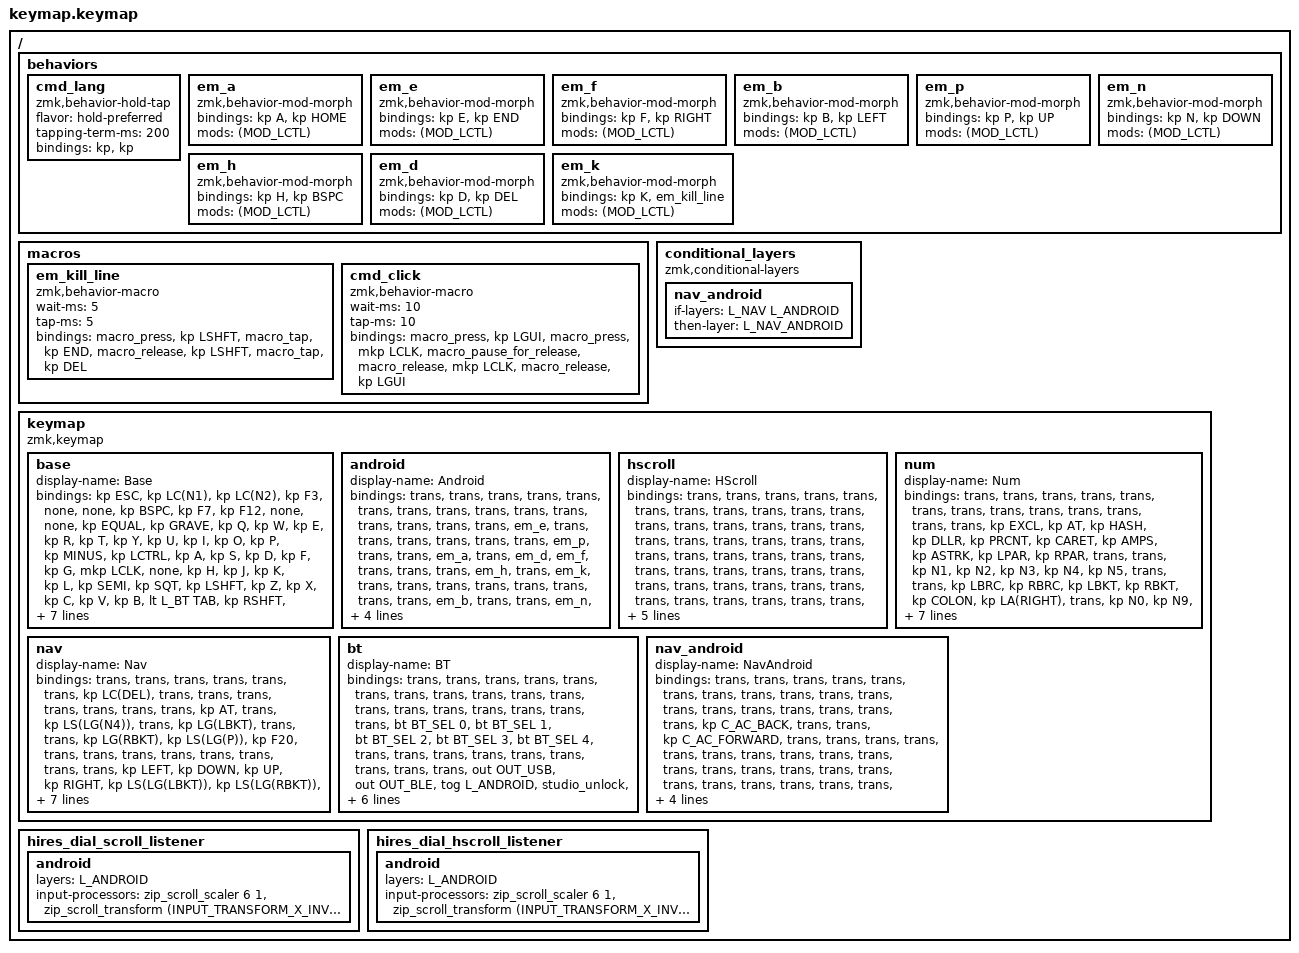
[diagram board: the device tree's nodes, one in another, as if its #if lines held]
/*
 * torabo-tsuki LP (L size) keymap
 *   - 右: トラックボール + 高分解能ダイヤル (central) / 左: モジュールなし (peripheral)
 *   - 右の BMP Boost 真下のキー (position 31) を高分解能ダイヤルモジュールに置換
 *     (BMP Boost Extender Mini 経由で接続。position 30 は通常のキー)
 *   - keymap_cheatsheet_keyball61-dual.pdf の配置をできるだけ再現 (マクロは未割当)
 *
 * Position map (L size, ダイヤル有効時):
 *
 *   0  1  2  3  4  5                    6  7  8  9 10 11
 *  12 13 14 15 16 17                   18 19 20 21 22 23
 *  24 25 26 27 28 29  30        [31]  32 33 34 35 36 37
 *  38 39 40 41 42 43  44          45   46 47 48 49 50 51
 *  52 53 54 55   56 57 58     59 60 (61 62) 63 64 65
 *                                    ^ボールで潰れる
 *  [31] = ダイヤルに置換 (スイッチなし)
 *  66 = ダイヤル押し込み (縦/横スクロールのトグル) / 回転は末尾の sensor-bindings で設定
 */

#include <behaviors.dtsi>
#include <dt-bindings/zmk/bt.h>
#include <dt-bindings/zmk/keys.h>
#include <dt-bindings/zmk/outputs.h>
#include <dt-bindings/zmk/pointing.h>
#include <dt-bindings/zmk/input_transform.h>

// レイヤー番号 (数字が大きいほど優先)
//   Android モードは Base の直上に置き、Num / Nav / BT の割り当てを上書きしないようにする
//   L_ANDROID を変えたら src/android_mode.c の ANDROID_MODE_LAYER も合わせる
#define L_BASE        0
#define L_ANDROID     1
#define L_HSCROLL     2
#define L_NUM         3
#define L_NAV         4
#define L_BT          5
#define L_NAV_ANDROID 6

#if defined(TORABO_TSUKI_LP_INPUT_HIRES_DIAL)
#include <behaviors/hires_dial.dtsi>
#endif

/ {
    behaviors {
        // タップで LANG (英数/かな)、長押し or 他キーと同時押しで修飾キー (⌘、Android モードの 57 は Ctrl)
        //   Mac は LANG1=かな / LANG2=英数 をそのまま解釈、Android (Gboard) でも IME 切替になる
        cmd_lang: cmd_lang {
            compatible = "zmk,behavior-hold-tap";
            #binding-cells = <2>;
            flavor = "hold-preferred";
            tapping-term-ms = <200>;
            bindings = <&kp>, <&kp>;
        };

        // Android 用 Emacs 風カーソル移動: 左 Ctrl (24) と同時押しのときだけ置き換える (Ctrl は外して送る)
        //   57 の長押しは Android モードでは右 Ctrl なので、57 + A / F などは普通の Ctrl ショートカットになる
        em_a: em_a {  // Ctrl+A → 行頭
            compatible = "zmk,behavior-mod-morph";
            #binding-cells = <0>;
            bindings = <&kp A>, <&kp HOME>;
            mods = <(MOD_LCTL)>;
        };
        em_e: em_e {  // Ctrl+E → 行末
            compatible = "zmk,behavior-mod-morph";
            #binding-cells = <0>;
            bindings = <&kp E>, <&kp END>;
            mods = <(MOD_LCTL)>;
        };
        em_f: em_f {  // Ctrl+F → →
            compatible = "zmk,behavior-mod-morph";
            #binding-cells = <0>;
            bindings = <&kp F>, <&kp RIGHT>;
            mods = <(MOD_LCTL)>;
        };
        em_b: em_b {  // Ctrl+B → ←
            compatible = "zmk,behavior-mod-morph";
            #binding-cells = <0>;
            bindings = <&kp B>, <&kp LEFT>;
            mods = <(MOD_LCTL)>;
        };
        em_p: em_p {  // Ctrl+P → ↑
            compatible = "zmk,behavior-mod-morph";
            #binding-cells = <0>;
            bindings = <&kp P>, <&kp UP>;
            mods = <(MOD_LCTL)>;
        };
        em_n: em_n {  // Ctrl+N → ↓
            compatible = "zmk,behavior-mod-morph";
            #binding-cells = <0>;
            bindings = <&kp N>, <&kp DOWN>;
            mods = <(MOD_LCTL)>;
        };
        em_h: em_h {  // Ctrl+H → Backspace
            compatible = "zmk,behavior-mod-morph";
            #binding-cells = <0>;
            bindings = <&kp H>, <&kp BSPC>;
            mods = <(MOD_LCTL)>;
        };
        em_d: em_d {  // Ctrl+D → Delete (カーソルの右を削除)
            compatible = "zmk,behavior-mod-morph";
            #binding-cells = <0>;
            bindings = <&kp D>, <&kp DEL>;
            mods = <(MOD_LCTL)>;
        };
        em_k: em_k {  // Ctrl+K → 行末まで削除 (下の em_kill_line マクロ)
            compatible = "zmk,behavior-mod-morph";
            #binding-cells = <0>;
            bindings = <&kp K>, <&em_kill_line>;
            mods = <(MOD_LCTL)>;
        };
    };

    macros {
        // Android 用 Ctrl+K: Shift+End で行末まで選択 → Delete
        //   行末で押した場合は選択が空なので Delete で次の行と結合される (Emacs と同じ)
        //   mod-morph の Ctrl マスクは K を離すと解除されるため、離す前に送り終わるよう間隔を短くしている
        em_kill_line: em_kill_line {
            compatible = "zmk,behavior-macro";
            #binding-cells = <0>;
            wait-ms = <5>;
            tap-ms = <5>;
            bindings
                = <&macro_press &kp LSHFT>
                , <&macro_tap &kp END>
                , <&macro_release &kp LSHFT>
                , <&macro_tap &kp DEL>
                ;
        };

        // ⌘ + 左クリック (押している間 ⌘ と左ボタンを押しっぱなし)
        cmd_click: cmd_click {
            compatible = "zmk,behavior-macro";
            #binding-cells = <0>;
            wait-ms = <10>;
            tap-ms = <10>;
            bindings
                = <&macro_press &kp LGUI>
                , <&macro_press &mkp LCLK>
                , <&macro_pause_for_release>
                , <&macro_release &mkp LCLK>
                , <&macro_release &kp LGUI>
                ;
        };
    };

    // Nav と Android モードが両方有効なときだけ NavAndroid レイヤーを有効にする
    conditional_layers {
        compatible = "zmk,conditional-layers";
        nav_android {
            if-layers = <L_NAV L_ANDROID>;
            then-layer = <L_NAV_ANDROID>;
        };
    };

    keymap {
        compatible = "zmk,keymap";

        // Layer 0: base
        base {
            display-name = "Base";
            bindings = <
&kp ESC    &kp LC(N1)         &kp LC(N2)  &kp F3   &none      &none                                                                    &kp BSPC  &kp F7  &kp F12    &none         &none                     &kp EQUAL
&kp GRAVE  &kp Q              &kp W       &kp E    &kp R      &kp T                                                                    &kp Y     &kp U   &kp I      &kp O         &kp P                     &kp MINUS
&kp LCTRL  &kp A              &kp S       &kp D    &kp F      &kp G      &mkp LCLK                            &none                    &kp H     &kp J   &kp K      &kp L         &kp SEMI                  &kp SQT
&kp LSHFT  &kp Z              &kp X       &kp C    &kp V      &kp B      &lt L_BT TAB                            &kp RSHFT                &kp N     &kp M   &kp COMMA  &kp DOT       &kp FSLH                  &kp BSLH
&none      &kp LALT           &none       &mo L_NAV &mo L_NUM     &cmd_lang LGUI LANG2   &kp SPACE    &lt L_NAV RET  &lt L_NUM LANG1   &none     &none          &cmd_lang RGUI LANG1  &mkp RCLK &mkp LCLK
#if defined(TORABO_TSUKI_LP_INPUT_HIRES_DIAL)
&tog L_HSCROLL
#endif
            >;
        };

        // Layer 1: Android モード (BT1 に切り替えると自動で ON、他の接続先で OFF: src/android_mode.c)
        //   BT レイヤーの 34 で手動トグルも可
        //   52 = ⌘、57 = タップで英数 / 長押しで右 Ctrl (Mac の ⌘ の代わり)
        //   A/E/F/B/P/N/H/D/K = 左 Ctrl (24) と同時押しで Emacs 風 (行頭/行末/矢印/Backspace/Delete/行末まで削除)。他は &trans
        //   ダイヤルの割り当ては持たない (下のレイヤーのものが使われる)
        //   ダイヤルのスクロールだけ、下の input-listener の上書きで速く・逆向きにする
        android {
            display-name = "Android";
            bindings = <
&trans  &trans  &trans  &trans  &trans  &trans                                                  &trans  &trans  &trans  &trans  &trans  &trans
&trans  &trans  &trans  &em_e  &trans  &trans  &trans  &trans  &trans  &trans  &em_p  &trans
&trans  &em_a  &trans  &em_d  &em_f  &trans  &trans  &trans  &em_h  &trans  &em_k  &trans  &trans  &trans
&trans  &trans  &trans  &trans  &trans  &em_b  &trans  &trans  &em_n  &trans  &trans  &trans  &trans  &trans
&kp LGUI  &trans  &trans  &trans  &trans  &cmd_lang RCTRL LANG2  &trans         &trans  &trans  &trans           &trans  &trans  &trans  &trans
#if defined(TORABO_TSUKI_LP_INPUT_HIRES_DIAL)
&trans
#endif
            >;
        };

        // Layer 2: ダイヤル横スクロール (ダイヤル押し込みでトグル)
        //   Base の直上に置くので、Num / Nav 中はそちらのダイヤル設定が優先される
        hscroll {
            display-name = "HScroll";
            bindings = <
&trans  &trans  &trans  &trans  &trans  &trans                                                  &trans  &trans  &trans  &trans  &trans  &trans
&trans  &trans  &trans  &trans  &trans  &trans                                                  &trans  &trans  &trans  &trans  &trans  &trans
&trans  &trans  &trans  &trans  &trans  &trans  &trans                         &trans           &trans  &trans  &trans  &trans  &trans  &trans
&trans  &trans  &trans  &trans  &trans  &trans  &trans                         &trans           &trans  &trans  &trans  &trans  &trans  &trans
&trans  &trans  &trans  &trans  &trans  &trans  &trans         &trans  &trans  &trans           &trans  &trans  &trans  &trans
#if defined(TORABO_TSUKI_LP_INPUT_HIRES_DIAL)
&trans
#endif
            >;
        };

        // Layer 3: 数字・記号 (右親指 ⌘ 長押し / 左 56 を押している間)
        num {
            display-name = "Num";
            bindings = <
&trans  &trans    &trans   &trans    &trans    &trans                                                   &trans     &trans    &trans    &trans    &trans     &trans
&trans  &kp EXCL  &kp AT   &kp HASH  &kp DLLR  &kp PRCNT                                                &kp CARET  &kp AMPS  &kp ASTRK &kp LPAR  &kp RPAR   &trans
&trans  &kp N1    &kp N2   &kp N3    &kp N4    &kp N5     &trans                       &trans           &kp LBRC   &kp RBRC  &kp LBKT  &kp RBKT  &kp COLON  &kp LA(RIGHT)
&trans  &kp N0    &kp N9   &kp N8    &kp N7    &kp N6     &kp LS(TAB)                  &kp LS(LA(SPACE)) &trans    &trans    &trans    &trans    &trans     &kp LS(LA(DOWN))
&trans  &trans    &trans   &trans    &trans    &trans     &trans       &trans  &trans  &trans           &trans     &trans    &trans    &cmd_click
#if defined(TORABO_TSUKI_LP_INPUT_HIRES_DIAL)
&trans
#endif
            >;
        };

        // Layer 4: カーソル・ショートカット (右親指 Enter 長押し / 左 55 を押している間)
        //   Macro0-4 の位置は &trans のまま
        //   23 = F20 → Karabiner が "- [ ] " を入力 (かなモードなら英数にして入力後かなに戻す)
        nav {
            display-name = "Nav";
            bindings = <
&trans  &trans  &trans  &trans  &trans          &trans                                                  &kp LC(DEL)         &trans              &trans              &trans              &trans                 &trans
&trans  &trans  &kp AT  &trans  &kp LS(LG(N4))  &trans                                                  &kp LG(LBKT)        &trans              &trans              &kp LG(RBKT)        &kp LS(LG(P))          &kp F20 
&trans  &trans  &trans  &trans  &trans          &trans  &trans                         &trans           &kp LEFT            &kp DOWN            &kp UP              &kp RIGHT           &kp LS(LG(LBKT))       &kp LS(LG(RBKT))
&trans  &trans  &trans  &trans  &kp LS(LG(V))   &trans  &trans                         &trans           &none               &none               &none               &none               &none                  &trans
&trans  &trans  &trans  &trans  &trans          &trans  &trans         &trans  &trans  &trans           &trans              &trans              &trans              &trans
#if defined(TORABO_TSUKI_LP_INPUT_HIRES_DIAL)
&trans
#endif
            >;
        };

        // Layer 5: (Keyball61 では空) 無線用に BT / 出力切替を右手側に配置 (左 Tab 長押し)
        //   35 = ZMK Studio のロック解除 (Studio でキーマップを変更する前に押す)
        bt {
            display-name = "BT";
            bindings = <
&trans  &trans  &trans  &trans  &trans  &trans                                                  &trans          &trans          &trans          &trans          &trans          &trans
&trans  &trans  &trans  &trans  &trans  &trans                                                  &bt BT_SEL 0    &bt BT_SEL 1    &bt BT_SEL 2    &bt BT_SEL 3    &bt BT_SEL 4    &trans
&trans  &trans  &trans  &trans  &trans  &trans  &trans                         &trans           &out OUT_USB    &out OUT_BLE    &tog L_ANDROID    &studio_unlock          &trans          &trans
&trans  &trans  &trans  &trans  &trans  &trans  &trans                         &trans           &trans          &trans          &trans          &trans          &bt BT_CLR      &trans
&trans  &trans  &trans  &trans  &trans  &trans  &trans         &trans  &trans  &trans           &trans          &trans          &trans          &trans
#if defined(TORABO_TSUKI_LP_INPUT_HIRES_DIAL)
&trans
#endif
            >;
        };

        // Layer 6: Nav + Android モードのとき自動で有効 (下の conditional_layers)
        //   Mac 用の ⌘[ / ⌘] の代わりに、Android の戻る / 進む (Consumer AC Back / Forward) を送る
        nav_android {
            display-name = "NavAndroid";
            bindings = <
&trans  &trans  &trans  &trans  &trans  &trans                                                  &trans          &trans  &trans  &trans  &trans  &trans
&trans  &trans  &trans  &trans  &trans  &trans                                                  &kp C_AC_BACK   &trans  &trans  &kp C_AC_FORWARD  &trans  &trans
&trans  &trans  &trans  &trans  &trans  &trans  &trans                         &trans           &trans          &trans  &trans  &trans  &trans  &trans
&trans  &trans  &trans  &trans  &trans  &trans  &trans                         &trans           &trans          &trans  &trans  &trans  &trans  &trans
&trans  &trans  &trans  &trans  &trans  &trans  &trans         &trans  &trans  &trans           &trans          &trans  &trans  &trans
#if defined(TORABO_TSUKI_LP_INPUT_HIRES_DIAL)
&trans
#endif
            >;
        };
    };
};

#if defined(TORABO_TSUKI_LP_INPUT_HIRES_DIAL)
// ダイヤル回転 (<入力 出力>: 48 1 = 48カウントで1段, 1回転≒26段)
//   Base=縦スクロール / HScroll=横スクロール / Num=横スクロール / Nav=音量
//   BT は設定なし (下のレイヤーの設定がそのまま使われる)
&{/keymap/base} {
    sensor-bindings = <&hires_dial_scroll 48 1>;
};

&{/keymap/hscroll} {
    sensor-bindings = <&hires_dial_hscroll 48 1>;
};

&{/keymap/num} {
    sensor-bindings = <&hires_dial_hscroll 48 1>;
};

&{/keymap/nav} {
    sensor-bindings = <&hires_dial_encoder C_VOL_UP C_VOL_DN>;
};

// Android モード (Layer 1) 中はダイヤルのスクロールを 6 倍速・縦横とも逆向きにする
//   (Mac はナチュラルスクロールで逆向き & 1段の移動量が大きいため)
//   音量 (Nav) はキー入力なので影響しない
/ {
    hires_dial_scroll_listener {
        android {
            layers = <L_ANDROID>;
            input-processors = <&zip_scroll_scaler 6 1>,
                               <&zip_scroll_transform (INPUT_TRANSFORM_X_INVERT | INPUT_TRANSFORM_Y_INVERT)>;
        };
    };

    hires_dial_hscroll_listener {
        android {
            layers = <L_ANDROID>;
            input-processors = <&zip_scroll_scaler 6 1>,
                               <&zip_scroll_transform (INPUT_TRANSFORM_X_INVERT | INPUT_TRANSFORM_Y_INVERT)>;
        };
    };
};
#endif
